VERSION "_"

NS_ :

BS_:

BU_: node_0 rec_node_0

VAL_TABLE_ enum_with_4_values 0 "enum_value_0" 1 "enum_value_1" 2 "enum_value_2" 3 "enum_value_3";
VAL_TABLE_ enum_signal_8_values 0 "enum_value_0" 1 "enum_value_1" 2 "enum_value_2" 3 "enum_value_3" 4 "enum_value_4" 5 "enum_value_5" 6 "enum_value_6" 7 "enum_value_7";
VAL_TABLE_ enum_signal_fixed_size 0 "enum_value_0" 127 "enum_value_127";

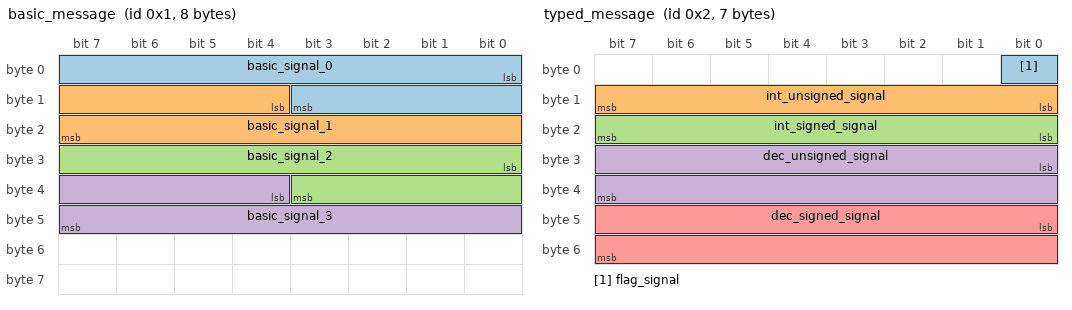
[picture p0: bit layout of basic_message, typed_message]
BO_ 1 basic_message : 8 node_0
 SG_ basic_signal_0 : 0|12@1+ (1,0) [0|4095] "" rec_node_0
 SG_ basic_signal_1 : 12|12@1+ (1,0) [0|4095] "" rec_node_0
 SG_ basic_signal_2 : 24|12@1+ (1,0) [0|4095] "" rec_node_0
 SG_ basic_signal_3 : 36|12@1+ (1,0) [0|4095] "" rec_node_0

BO_ 2 typed_message : 7 node_0
 SG_ flag_signal : 0|1@1+ (1,0) [0|1] "" rec_node_0
 SG_ int_unsigned_signal : 8|8@1+ (1,0) [0|255] "" rec_node_0
 SG_ int_signed_signal : 16|8@1- (1,0) [-128|127] "" rec_node_0
 SG_ dec_unsigned_signal : 24|16@1+ (0.5,100.5) [100.5|32868.5] "V" rec_node_0
 SG_ dec_signed_signal : 40|16@1- (0.5,100.5) [-16484.5|16484] "V" rec_node_0

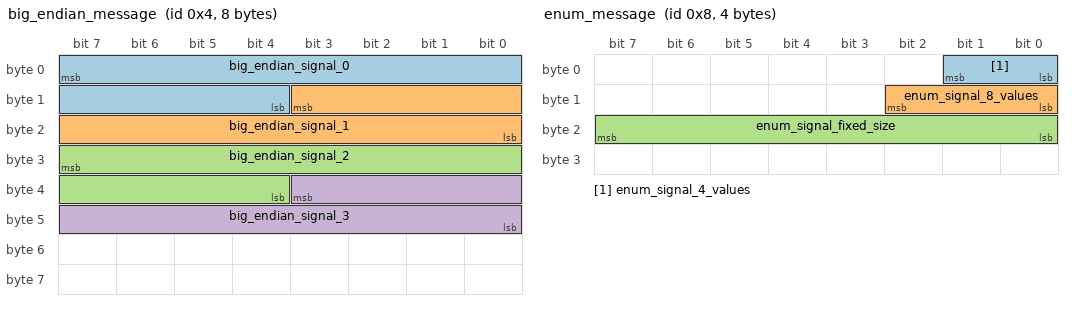
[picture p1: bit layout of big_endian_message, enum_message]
BO_ 4 big_endian_message : 8 node_0
 SG_ big_endian_signal_0 : 7|12@0+ (1,0) [0|4095] "" rec_node_0
 SG_ big_endian_signal_1 : 11|12@0+ (1,0) [0|4095] "" rec_node_0
 SG_ big_endian_signal_2 : 31|12@0+ (1,0) [0|4095] "" rec_node_0
 SG_ big_endian_signal_3 : 35|12@0+ (1,0) [0|4095] "" rec_node_0

BO_ 8 enum_message : 4 node_0
 SG_ enum_signal_4_values : 0|2@1+ (1,0) [0|3] "" rec_node_0
 SG_ enum_signal_8_values : 8|3@1+ (1,0) [0|7] "" rec_node_0
 SG_ enum_signal_fixed_size : 16|8@1+ (1,0) [0|128] "" rec_node_0

BO_ 16 mux_message : 8 node_0
 SG_ top_muxor M : 0|8@1+ (1,0) [0|255] "" rec_node_0
 SG_ top_signal_in_0 m0 : 8|8@1+ (1,0) [0|255] "" rec_node_0
 SG_ top_signal_in_255 m255 : 8|8@1+ (1,0) [0|255] "" rec_node_0
 SG_ top_signal_in_0_2 m0 : 16|8@1+ (1,0) [0|255] "" rec_node_0
 SG_ top_inner_muxor m1M : 8|8@1+ (1,0) [0|255] "" rec_node_0
 SG_ top_inner_signal_in_0 m0 : 16|8@1+ (1,0) [0|255] "" rec_node_0
 SG_ top_inner_signal_in_255 m255 : 16|8@1+ (1,0) [0|255] "" rec_node_0
 SG_ base_signal : 24|16@1+ (1,0) [0|255] "" rec_node_0
 SG_ bottom_inner_signal_in_0 m0 : 40|8@1+ (1,0) [0|255] "" rec_node_0
 SG_ bottom_inner_signal_in_255 m255 : 40|8@1+ (1,0) [0|255] "" rec_node_0
 SG_ bottom_inner_muxor m1M : 48|8@1+ (1,0) [0|255] "" rec_node_0
 SG_ bottom_signal_in_0_2 m0 : 40|8@1+ (1,0) [0|255] "" rec_node_0
 SG_ bottom_signal_in_0 m0 : 48|8@1+ (1,0) [0|255] "" rec_node_0
 SG_ bottom_signal_in_255 m255 : 48|8@1+ (1,0) [0|255] "" rec_node_0
 SG_ bottom_muxor M : 56|8@1+ (1,0) [0|255] "" rec_node_0

BO_ 32 simple_mux_message : 4 node_0
 SG_ muxor M : 0|8@1+ (1,0) [0|255] "" rec_node_0
 SG_ signal_in_0 m0 : 8|8@1+ (1,0) [0|255] "" rec_node_0
 SG_ signal_in_1 m1 : 8|8@1+ (1,0) [0|255] "" rec_node_0
 SG_ signal_in_2 m2 : 16|8@1+ (1,0) [0|255] "" rec_node_0

VAL_ 8 enum_signal_4_values 0 "enum_value_0" 1 "enum_value_1" 2 "enum_value_2" 3 "enum_value_3";
VAL_ 8 enum_signal_8_values 0 "enum_value_0" 1 "enum_value_1" 2 "enum_value_2" 3 "enum_value_3" 4 "enum_value_4" 5 "enum_value_5" 6 "enum_value_6" 7 "enum_value_7";
VAL_ 8 enum_signal_fixed_size 0 "enum_value_0" 127 "enum_value_127";

SG_MUL_VAL_ 16 top_signal_in_0 top_muxor 0-0;
SG_MUL_VAL_ 16 top_signal_in_255 top_muxor 255-255;
SG_MUL_VAL_ 16 top_signal_in_0_2 top_muxor 0-0, 2-2;
SG_MUL_VAL_ 16 top_inner_muxor top_muxor 1-1;
SG_MUL_VAL_ 16 top_inner_signal_in_0 top_inner_muxor 0-0;
SG_MUL_VAL_ 16 top_inner_signal_in_255 top_inner_muxor 255-255;
SG_MUL_VAL_ 16 bottom_inner_muxor bottom_muxor 1-1;
SG_MUL_VAL_ 16 bottom_inner_signal_in_0 bottom_inner_muxor 0-0;
SG_MUL_VAL_ 16 bottom_inner_signal_in_255 bottom_inner_muxor 255-255;
SG_MUL_VAL_ 16 bottom_signal_in_0 bottom_muxor 0-0;
SG_MUL_VAL_ 16 bottom_signal_in_255 bottom_muxor 255-255;
SG_MUL_VAL_ 16 bottom_signal_in_0_2 bottom_muxor 0-0, 2-2;
